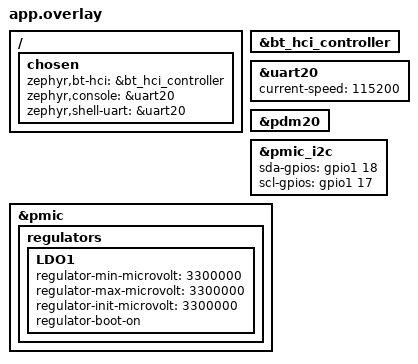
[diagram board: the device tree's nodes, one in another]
/*
 * app.overlay — HiveInside adjustments to the XIAO nRF54LM20A board DT.
 *
 * Kept identical to zephyr/app.overlay (the copy PlatformIO's Seeed Zephyr
 * builder reads); edit both together.
 *
 * Everything else the firmware needs is already enabled by the upstream
 * board definition: i2c22 (the XIAO header bus, external SHT40), i2c30
 * (internal bus with the LSM6DS3TR-C at 0x6a), and the led0/sw0 aliases.
 * The PMIC bit-banged I2C pins are overridden below to match the Sense
 * board routing used by Seeed's nRF54LM20A peripheral examples.
 */

/* Bluetooth HCI: the SoC devicetree ships the software link-layer
 * controller node disabled, and not every board definition revision enables
 * it or sets the chosen entry (upstream Zephyr's does, the pinned Seeed
 * platform's does not) — so do both here. Redundant where the board already
 * did it, required everywhere else. */
/ {
	chosen {
		zephyr,bt-hci = &bt_hci_controller;

		/* Console routing (see prj.conf for the full explanation).
		 *
		 * uart20 (P1.11 TX / P1.10 RX) is wired to the on-board SAMD11
		 * CMSIS-DAP debugger, which bridges it to a USB CDC ACM port
		 * (/dev/ttyACM0) over the same USB-C cable used for flashing.
		 * The board definition already chooses uart20; re-assert it
		 * here so the application console does not silently move if a
		 * future board-definition bump changes the default. The XIAO
		 * header UART is uart21 on D6/D7 — deliberately NOT the console. */
		zephyr,console = &uart20;
		zephyr,shell-uart = &uart20;
	};
};

&bt_hci_controller {
	status = "okay";
};

/* Belt-and-suspenders: the board definition already enables uart20 at
 * 115200 8N1; keep it explicit next to the console choice above. */
&uart20 {
	status = "okay";
	current-speed = <115200>;
};

/* On-board PDM microphone (MSM261DGT006). The board definition provides
 * pinctrl and clock-source but leaves the controller disabled. */
&pdm20 {
	status = "okay";
};

/* The early board DTS used GPIO1.15/16 for this bus.  The Sense module
 * routes the nPM1300 to GPIO1.18 (SDA) and GPIO1.17 (SCL); without this
 * override the PMIC cannot be reached, leaving the sensor rail and battery
 * gauge unavailable. */
&pmic_i2c {
	sda-gpios = <&gpio1 18 GPIO_ACTIVE_HIGH>;
	scl-gpios = <&gpio1 17 GPIO_ACTIVE_HIGH>;
	status = "okay";
};

/* The Sense module powers the IMU and the PDM microphone from the nPM1300's
 * LDO1, but the stock board definition pins LDO1 to 1.8 V — too low for
 * either part. Pin min/max/init to 3.3 V and enable the rail at boot so it is
 * already correct before any code runs; src/power.c then re-asserts 3.3 V and
 * waits for the parts to settle. regulator-init-microvolt makes the rail
 * correct even if power.c is ever compiled out (belt and suspenders). */
&pmic {
	regulators {
		LDO1 {
			regulator-min-microvolt = <3300000>;
			regulator-max-microvolt = <3300000>;
			regulator-init-microvolt = <3300000>;
			regulator-boot-on;
		};
	};
};
